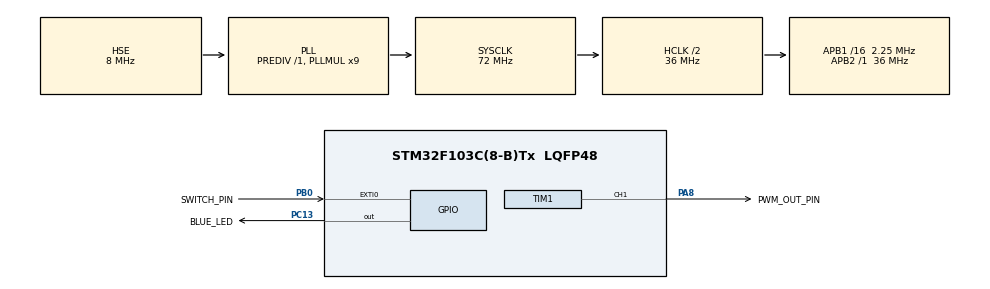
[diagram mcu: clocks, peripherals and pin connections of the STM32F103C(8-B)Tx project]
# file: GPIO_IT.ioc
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Mcu.Family=STM32F1
RCC.PLLSourceVirtual=RCC_PLLSOURCE_HSE
PD1-OSC_OUT.Mode=HSE-External-Oscillator
PC13-TAMPER-RTC.Signal=GPIO_Output
PB0.GPIO_Label=SWITCH_PIN
NVIC.TIM1_UP_IRQn=true\:0\:0\:false\:false\:true\:true\:true
PD0-OSC_IN.Signal=RCC_OSC_IN
TIM1.Pulse-PWM\ Generation1\ CH1=500
RCC.APB1CLKDivider=RCC_HCLK_DIV16
RCC.SYSCLKSource=RCC_SYSCLKSOURCE_PLLCLK
ProjectManager.StackSize=0x400
TIM1.ClockDivision=TIM_CLOCKDIVISION_DIV1
PD1-OSC_OUT.Signal=RCC_OSC_OUT
PA13.Signal=SYS_JTMS-SWDIO
PA8.GPIO_Label=PWM_OUT_PIN
TIM1.Prescaler=720
SH.S_TIM1_CH1.0=TIM1_CH1,PWM Generation1 CH1
ProjectManager.TargetToolchain=STM32CubeIDE
RCC.HCLKFreq_Value=36000000
RCC.APB2TimFreq_Value=36000000
RCC.USBFreq_Value=72000000
RCC.AHBFreq_Value=36000000
PD0-OSC_IN.Mode=HSE-External-Oscillator
board=custom
PC13-TAMPER-RTC.GPIO_Label=BLUE_LED
RCC.PLLMUL=RCC_PLL_MUL9
PB0.GPIO_ModeDefaultEXTI=GPIO_MODE_IT_RISING_FALLING
RCC.APB2Freq_Value=36000000
TIM1.Channel-PWM\ Generation1\ CH1=TIM_CHANNEL_1
PA14.Mode=Serial_Wire
PA8.Signal=S_TIM1_CH1
RCC.AHBCLKDivider=RCC_SYSCLK_DIV2
PA13.Mode=Serial_Wire
Mcu.Name=STM32F103C(8-B)Tx
VP_TIM1_VS_ClockSourceINT.Mode=Internal
NVIC.EXTI0_IRQn=true\:0\:0\:false\:false\:true\:true\:true
RCC.SYSCLKFreq_VALUE=72000000
Mcu.Package=LQFP48
PA14.Signal=SYS_JTCK-SWCLK
ProjectManager.HeapSize=0x200
NVIC.PriorityGroup=NVIC_PRIORITYGROUP_4
RCC.APB1TimFreq_Value=4500000
TIM1.Period=999
RCC.APB1Freq_Value=2250000
PB0.Signal=GPXTI0
PB0.GPIO_PuPd=GPIO_PULLUP

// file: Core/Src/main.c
/* USER CODE BEGIN Header */
/**
  ******************************************************************************
  * @file           : main.c
  * @brief          : Main program body
  ******************************************************************************
  * @attention
  *
  * <h2><center>&copy; Copyright (c) 2021 STMicroelectronics.
  * All rights reserved.</center></h2>
  *
  * This software component is licensed by ST under BSD 3-Clause license,
  * the "License"; You may not use this file except in compliance with the
  * License. You may obtain a copy of the License at:
  *                        opensource.org/licenses/BSD-3-Clause
  *
  ******************************************************************************
  */
/* USER CODE END Header */
#include "main.h"

TIM_HandleTypeDef htim1;

void SystemClock_Config(void);
static void MX_GPIO_Init(void);
static void MX_TIM1_Init(void);

/* USER CODE BEGIN 0 */
uint8_t touchCount = 0;
uint8_t prevState = 1;
/* USER CODE END 0 */

int main(void)
{

  /* MCU Configuration--------------------------------------------------------*/

  /* Reset of all peripherals, Initializes the Flash interface and the Systick. */
  HAL_Init();

  /* Configure the system clock */
  SystemClock_Config();

  /* Initialize all configured peripherals */
  MX_GPIO_Init();
  MX_TIM1_Init();
  /* USER CODE BEGIN 2 */
  HAL_GPIO_WritePin(BLUE_LED_GPIO_Port, BLUE_LED_Pin, GPIO_PIN_SET);
  /* USER CODE END 2 */

  /* Infinite loop */
  while (1)
  {

  }
}

void SystemClock_Config(void)
{
  RCC_OscInitTypeDef RCC_OscInitStruct = {0};
  RCC_ClkInitTypeDef RCC_ClkInitStruct = {0};

  /** Initializes the RCC Oscillators according to the specified parameters
  * in the RCC_OscInitTypeDef structure.
  */
  RCC_OscInitStruct.OscillatorType = RCC_OSCILLATORTYPE_HSE;
  RCC_OscInitStruct.HSEState = RCC_HSE_ON;
  RCC_OscInitStruct.HSEPredivValue = RCC_HSE_PREDIV_DIV1;
  RCC_OscInitStruct.HSIState = RCC_HSI_ON;
  RCC_OscInitStruct.PLL.PLLState = RCC_PLL_ON;
  RCC_OscInitStruct.PLL.PLLSource = RCC_PLLSOURCE_HSE;
  RCC_OscInitStruct.PLL.PLLMUL = RCC_PLL_MUL9;
  if (HAL_RCC_OscConfig(&RCC_OscInitStruct) != HAL_OK)
  {
    Error_Handler();
  }
  /** Initializes the CPU, AHB and APB buses clocks
  */
  RCC_ClkInitStruct.ClockType = RCC_CLOCKTYPE_HCLK|RCC_CLOCKTYPE_SYSCLK
                              |RCC_CLOCKTYPE_PCLK1|RCC_CLOCKTYPE_PCLK2;
  RCC_ClkInitStruct.SYSCLKSource = RCC_SYSCLKSOURCE_PLLCLK;
  RCC_ClkInitStruct.AHBCLKDivider = RCC_SYSCLK_DIV2;
  RCC_ClkInitStruct.APB1CLKDivider = RCC_HCLK_DIV16;
  RCC_ClkInitStruct.APB2CLKDivider = RCC_HCLK_DIV1;

  if (HAL_RCC_ClockConfig(&RCC_ClkInitStruct, FLASH_LATENCY_2) != HAL_OK)
  {
    Error_Handler();
  }
}

static void MX_TIM1_Init(void)
{

  TIM_ClockConfigTypeDef sClockSourceConfig = {0};
  TIM_MasterConfigTypeDef sMasterConfig = {0};
  TIM_OC_InitTypeDef sConfigOC = {0};
  TIM_BreakDeadTimeConfigTypeDef sBreakDeadTimeConfig = {0};

  htim1.Instance = TIM1;
  htim1.Init.Prescaler = 720;
  htim1.Init.CounterMode = TIM_COUNTERMODE_UP;
  htim1.Init.Period = 999;
  htim1.Init.ClockDivision = TIM_CLOCKDIVISION_DIV1;
  htim1.Init.RepetitionCounter = 0;
  htim1.Init.AutoReloadPreload = TIM_AUTORELOAD_PRELOAD_DISABLE;
  if (HAL_TIM_Base_Init(&htim1) != HAL_OK)
  {
    Error_Handler();
  }
  sClockSourceConfig.ClockSource = TIM_CLOCKSOURCE_INTERNAL;
  if (HAL_TIM_ConfigClockSource(&htim1, &sClockSourceConfig) != HAL_OK)
  {
    Error_Handler();
  }
  if (HAL_TIM_PWM_Init(&htim1) != HAL_OK)
  {
    Error_Handler();
  }
  sMasterConfig.MasterOutputTrigger = TIM_TRGO_RESET;
  sMasterConfig.MasterSlaveMode = TIM_MASTERSLAVEMODE_DISABLE;
  if (HAL_TIMEx_MasterConfigSynchronization(&htim1, &sMasterConfig) != HAL_OK)
  {
    Error_Handler();
  }
  sConfigOC.OCMode = TIM_OCMODE_PWM1;
  sConfigOC.Pulse = 500;
  sConfigOC.OCPolarity = TIM_OCPOLARITY_HIGH;
  sConfigOC.OCNPolarity = TIM_OCNPOLARITY_HIGH;
  sConfigOC.OCFastMode = TIM_OCFAST_DISABLE;
  sConfigOC.OCIdleState = TIM_OCIDLESTATE_RESET;
  sConfigOC.OCNIdleState = TIM_OCNIDLESTATE_RESET;
  if (HAL_TIM_PWM_ConfigChannel(&htim1, &sConfigOC, TIM_CHANNEL_1) != HAL_OK)
  {
    Error_Handler();
  }
  sBreakDeadTimeConfig.OffStateRunMode = TIM_OSSR_DISABLE;
  sBreakDeadTimeConfig.OffStateIDLEMode = TIM_OSSI_DISABLE;
  sBreakDeadTimeConfig.LockLevel = TIM_LOCKLEVEL_OFF;
  sBreakDeadTimeConfig.DeadTime = 0;
  sBreakDeadTimeConfig.BreakState = TIM_BREAK_DISABLE;
  sBreakDeadTimeConfig.BreakPolarity = TIM_BREAKPOLARITY_HIGH;
  sBreakDeadTimeConfig.AutomaticOutput = TIM_AUTOMATICOUTPUT_DISABLE;
  if (HAL_TIMEx_ConfigBreakDeadTime(&htim1, &sBreakDeadTimeConfig) != HAL_OK)
  {
    Error_Handler();
  }
  HAL_TIM_MspPostInit(&htim1);

}

static void MX_GPIO_Init(void)
{
  GPIO_InitTypeDef GPIO_InitStruct = {0};

  /* GPIO Ports Clock Enable */
  __HAL_RCC_GPIOC_CLK_ENABLE();
  __HAL_RCC_GPIOD_CLK_ENABLE();
  __HAL_RCC_GPIOB_CLK_ENABLE();
  __HAL_RCC_GPIOA_CLK_ENABLE();

  /*Configure GPIO pin Output Level */
  HAL_GPIO_WritePin(BLUE_LED_GPIO_Port, BLUE_LED_Pin, GPIO_PIN_RESET);

  /*Configure GPIO pin : BLUE_LED_Pin */
  GPIO_InitStruct.Pin = BLUE_LED_Pin;
  GPIO_InitStruct.Mode = GPIO_MODE_OUTPUT_PP;
  GPIO_InitStruct.Pull = GPIO_NOPULL;
  GPIO_InitStruct.Speed = GPIO_SPEED_FREQ_LOW;
  HAL_GPIO_Init(BLUE_LED_GPIO_Port, &GPIO_InitStruct);

  /*Configure GPIO pin : SWITCH_PIN_Pin */
  GPIO_InitStruct.Pin = SWITCH_PIN_Pin;
  GPIO_InitStruct.Mode = GPIO_MODE_IT_RISING_FALLING;
  GPIO_InitStruct.Pull = GPIO_PULLUP;
  HAL_GPIO_Init(SWITCH_PIN_GPIO_Port, &GPIO_InitStruct);

  /* EXTI interrupt init*/
  HAL_NVIC_SetPriority(EXTI0_IRQn, 0, 0);
  HAL_NVIC_EnableIRQ(EXTI0_IRQn);

}

/* USER CODE BEGIN 4 */
void HAL_GPIO_EXTI_Callback(uint16_t GPIO_Pin){
	HAL_NVIC_DisableIRQ(SWITCH_PIN_EXTI_IRQn);
	if(SWITCH_PIN_Pin == GPIO_Pin){
	    HAL_TIM_Base_Start_IT(&htim1);
	}
}
void HAL_TIM_PeriodElapsedCallback(TIM_HandleTypeDef *htim){
	uint8_t current;
	current = HAL_GPIO_ReadPin(SWITCH_PIN_GPIO_Port, SWITCH_PIN_Pin);
	if((0 == current) && (1 == prevState)){
		HAL_GPIO_TogglePin(BLUE_LED_GPIO_Port, BLUE_LED_Pin);
		touchCount++;
	}
	prevState = current;
	HAL_TIM_Base_Stop_IT(htim);
	HAL_NVIC_EnableIRQ(SWITCH_PIN_EXTI_IRQn);
}

/* USER CODE END 4 */

void Error_Handler(void)
{
  __disable_irq();
  while (1)
  {
  }
}

/************************ (C) COPYRIGHT STMicroelectronics *****END OF FILE****/
